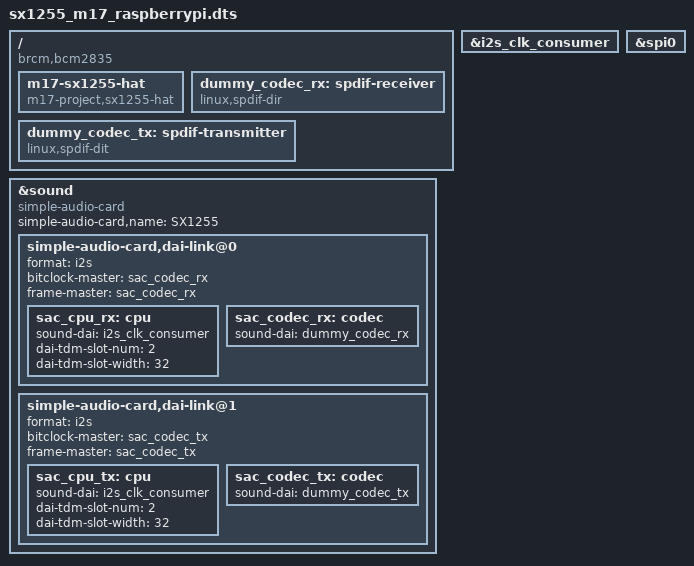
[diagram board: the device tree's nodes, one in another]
// SPDX-License-Identifier: MIT
//
// Device tree overlay for the M17 Project SX1255 HAT.
// The SX1255 supplies the I2S clocks, so the Raspberry Pi is the clock
// consumer. SPI is used only for the SX1255 register interface.

/dts-v1/;
/plugin/;

/ {
	compatible = "brcm,bcm2835";

	fragment@0 {
		target = <&i2s_clk_consumer>;
		__overlay__ {
			status = "okay";
		};
	};

	fragment@1 {
		target-path = "/";
		__overlay__ {
			// SoapySX uses this node to select the M17 pinout when
			// board=auto. No kernel driver binds to it.
			m17-sx1255-hat {
				compatible = "m17-project,sx1255-hat";
				status = "okay";
			};

			dummy_codec_rx: spdif-receiver {
				compatible = "linux,spdif-dir";
				status = "okay";
				#sound-dai-cells = <0>;
			};
			dummy_codec_tx: spdif-transmitter {
				compatible = "linux,spdif-dit";
				status = "okay";
				#sound-dai-cells = <0>;
			};
		};
	};

	fragment@2 {
		target = <&sound>;
		__overlay__ {
			compatible = "simple-audio-card";
			status = "okay";

			simple-audio-card,name = "SX1255";

			simple-audio-card,dai-link@0 {
				format = "i2s";
				bitclock-master = <&sac_codec_rx>;
				frame-master = <&sac_codec_rx>;

				sac_cpu_rx: cpu {
					sound-dai = <&i2s_clk_consumer>;
					dai-tdm-slot-num = <2>;
					dai-tdm-slot-width = <32>;
				};
				sac_codec_rx: codec {
					sound-dai = <&dummy_codec_rx>;
				};
			};
			simple-audio-card,dai-link@1 {
				format = "i2s";
				bitclock-master = <&sac_codec_tx>;
				frame-master = <&sac_codec_tx>;

				sac_cpu_tx: cpu {
					sound-dai = <&i2s_clk_consumer>;
					dai-tdm-slot-num = <2>;
					dai-tdm-slot-width = <32>;
				};
				sac_codec_tx: codec {
					sound-dai = <&dummy_codec_tx>;
				};
			};
		};
	};

	fragment@3 {
		target = <&spi0>;
		__overlay__ {
			status = "okay";
		};
	};
};
